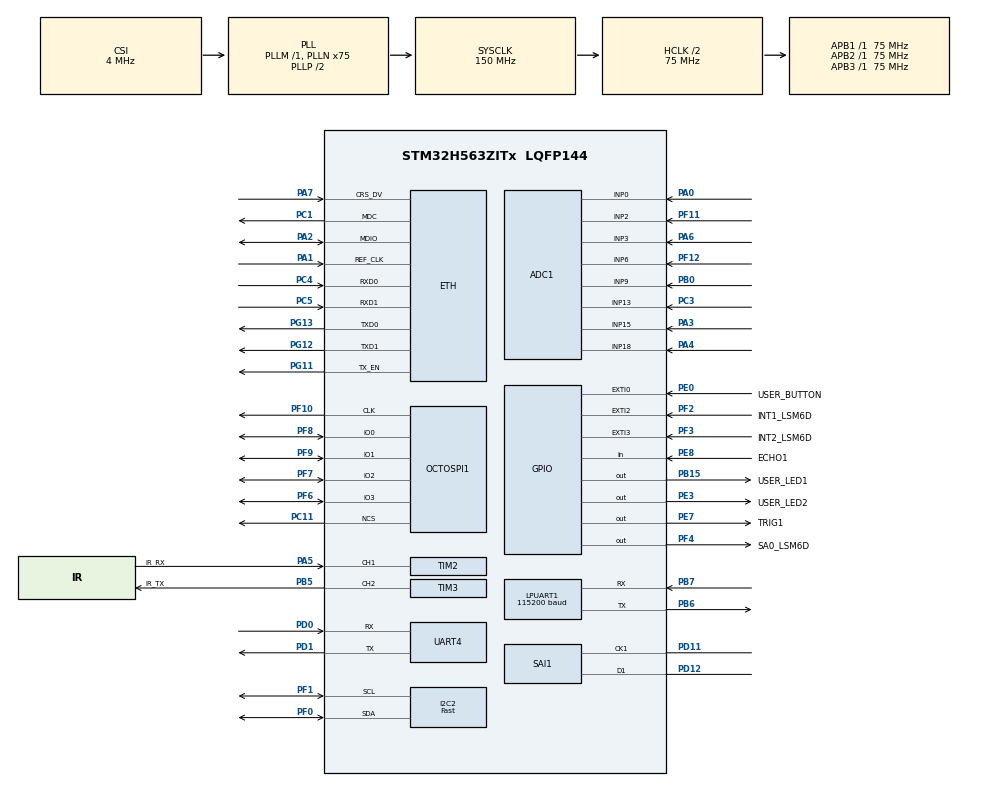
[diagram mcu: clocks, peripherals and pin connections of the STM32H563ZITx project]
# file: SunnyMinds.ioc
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ADC1.Channel-1\#ChannelRegularConversion=ADC_CHANNEL_2
ADC1.Channel-2\#ChannelRegularConversion=ADC_CHANNEL_6
ADC1.Channel-3\#ChannelRegularConversion=ADC_CHANNEL_18
ADC1.Channel-4\#ChannelRegularConversion=ADC_CHANNEL_3
ADC1.Channel-5\#ChannelRegularConversion=ADC_CHANNEL_0
ADC1.Channel-6\#ChannelRegularConversion=ADC_CHANNEL_9
ADC1.Channel-7\#ChannelRegularConversion=ADC_CHANNEL_15
ADC1.Channel-8\#ChannelRegularConversion=ADC_CHANNEL_13
ADC1.ClockPrescaler=ADC_CLOCK_ASYNC_DIV32
ADC1.ContinuousConvMode=ENABLE
ADC1.DMAContinuousRequests=ENABLE
ADC1.MonitoredBy-1\#ChannelRegularConversion=__NULL
ADC1.MonitoredBy-2\#ChannelRegularConversion=__NULL
ADC1.MonitoredBy-3\#ChannelRegularConversion=__NULL
ADC1.MonitoredBy-4\#ChannelRegularConversion=__NULL
ADC1.MonitoredBy-5\#ChannelRegularConversion=__NULL
ADC1.MonitoredBy-6\#ChannelRegularConversion=__NULL
ADC1.MonitoredBy-7\#ChannelRegularConversion=__NULL
ADC1.MonitoredBy-8\#ChannelRegularConversion=__NULL
ADC1.NbrOfConversion=8
ADC1.NbrOfConversionFlag=1
ADC1.OffsetNumber-1\#ChannelRegularConversion=ADC_OFFSET_NONE
ADC1.OffsetNumber-2\#ChannelRegularConversion=ADC_OFFSET_NONE
ADC1.OffsetNumber-3\#ChannelRegularConversion=ADC_OFFSET_NONE
ADC1.OffsetNumber-4\#ChannelRegularConversion=ADC_OFFSET_NONE
ADC1.OffsetNumber-5\#ChannelRegularConversion=ADC_OFFSET_NONE
ADC1.OffsetNumber-6\#ChannelRegularConversion=ADC_OFFSET_NONE
ADC1.OffsetNumber-7\#ChannelRegularConversion=ADC_OFFSET_NONE
ADC1.OffsetNumber-8\#ChannelRegularConversion=ADC_OFFSET_NONE
ADC1.Rank-1\#ChannelRegularConversion=1
ADC1.Rank-2\#ChannelRegularConversion=2
ADC1.Rank-3\#ChannelRegularConversion=3
ADC1.Rank-4\#ChannelRegularConversion=4
ADC1.Rank-5\#ChannelRegularConversion=5
ADC1.Rank-6\#ChannelRegularConversion=6
ADC1.Rank-7\#ChannelRegularConversion=7
ADC1.Rank-8\#ChannelRegularConversion=8
ADC1.SamplingTime-1\#ChannelRegularConversion=ADC_SAMPLETIME_247CYCLES_5
ADC1.SamplingTime-2\#ChannelRegularConversion=ADC_SAMPLETIME_247CYCLES_5
ADC1.SamplingTime-3\#ChannelRegularConversion=ADC_SAMPLETIME_247CYCLES_5
ADC1.SamplingTime-4\#ChannelRegularConversion=ADC_SAMPLETIME_640CYCLES_5
ADC1.SamplingTime-5\#ChannelRegularConversion=ADC_SAMPLETIME_247CYCLES_5
ADC1.SamplingTime-6\#ChannelRegularConversion=ADC_SAMPLETIME_247CYCLES_5
ADC1.SamplingTime-7\#ChannelRegularConversion=ADC_SAMPLETIME_247CYCLES_5
ADC1.SamplingTime-8\#ChannelRegularConversion=ADC_SAMPLETIME_247CYCLES_5
ADC1.master=1
BOOTPATH.BootPathName=LEGACY
BOOTPATH.UserSelectedBootPath=LEGACY
CORTEX_M33_NS.userName=CORTEX_M33
ETH.MediaInterface=HAL_ETH_RMII_MODE
GPDMA1.CIRCULARMODE_GPDMACH2=ENABLE
GPDMA1.CIRCULARMODE_GPDMACH7=ENABLE
GPDMA1.DESTDATAWIDTH_GPDMACH1=DMA_DEST_DATAWIDTH_WORD
GPDMA1.DESTDATAWIDTH_GPDMACH2=DMA_DEST_DATAWIDTH_HALFWORD
GPDMA1.DESTDATAWIDTH_GPDMACH7=DMA_DEST_DATAWIDTH_HALFWORD
GPDMA1.DESTINC_GPDMACH1=DMA_DINC_INCREMENTED
GPDMA1.DESTINC_GPDMACH2=DMA_DINC_INCREMENTED
GPDMA1.DESTINC_GPDMACH7=DMA_DINC_INCREMENTED
GPDMA1.IPHANDLE_GPDMACH1-SIMPLEREQUEST_GPDMACH1=__NULL
GPDMA1.IPHANDLE_GPDMACH2-SIMPLEREQUEST_GPDMACH2=__NULL
GPDMA1.IPHANDLE_GPDMACH7-SIMPLEREQUEST_GPDMACH7=__NULL
GPDMA1.LINKALLOCATEDPORT_CIRCULAR_GPDMACH2=DMA_LINK_ALLOCATED_PORT1
GPDMA1.REQUEST_GPDMACH1=GPDMA1_REQUEST_TIM2_CH1
GPDMA1.REQUEST_GPDMACH2=GPDMA1_REQUEST_SAI1_A
GPDMA1.REQUEST_GPDMACH7=GPDMA1_REQUEST_ADC1
GPDMA1.SRCDATAWIDTH_GPDMACH1=DMA_SRC_DATAWIDTH_HALFWORD
GPDMA1.SRCDATAWIDTH_GPDMACH2=DMA_SRC_DATAWIDTH_HALFWORD
GPDMA1.SRCDATAWIDTH_GPDMACH7=DMA_SRC_DATAWIDTH_HALFWORD
GPDMA1.TRANSFERALLOCATEDPORTDEST_GPDMACH1=DMA_DEST_ALLOCATED_PORT1
GPDMA1.TRANSFERALLOCATEDPORTDEST_GPDMACH2=DMA_DEST_ALLOCATED_PORT1
GPDMA1.TRANSFERALLOCATEDPORTSRC_GPDMACH1=DMA_SRC_ALLOCATED_PORT1
GPDMA1.TRANSFERALLOCATEDPORTSRC_GPDMACH2=DMA_SRC_ALLOCATED_PORT1
I2C2.I2C_Speed_Mode=I2C_Fast
I2C2.Timing=0x00702787
LPUART1.BaudRate=115200
Mcu.Family=STM32H5
Mcu.Name=STM32H563ZITx
Mcu.Package=LQFP144
NETXDUO.ETH_ON=1
NETXDUO.LAN_8742=1
NETXDUO.NX_APP_IP_INSTANCE_THREAD_SIZE=2*1024
NETXDUO.NX_APP_MEM_POOL_SIZE=30*1024
NETXDUO.NX_APP_PACKET_POOL_SIZE=10
NETXDUO.NX_APP_THREAD_STACK_SIZE=2*1024
NETXDUO.NX_ENABLE_INTERFACE_CAPABILITY=true
NETXDUO.NetXDuo_Generate_Init_Code=true
NVIC.ETH_IRQn=true\:0\:0\:false\:false\:true\:false\:true\:true\:true
NVIC.EXTI0_IRQn=true\:0\:0\:false\:false\:true\:false\:true\:true\:true
NVIC.GPDMA1_Channel1_IRQn=true\:0\:0\:false\:false\:true\:true\:false\:true\:true
NVIC.GPDMA1_Channel2_IRQn=true\:0\:0\:false\:false\:true\:true\:false\:true\:true
NVIC.GPDMA1_Channel7_IRQn=true\:0\:0\:false\:false\:true\:true\:false\:true\:true
NVIC.LPUART1_IRQn=true\:0\:0\:false\:false\:true\:false\:true\:true\:true
NVIC.PriorityGroup=NVIC_PRIORITYGROUP_4
NVIC.TIM17_IRQn=true\:0\:0\:false\:false\:true\:false\:true\:true\:true
NVIC.TIM3_IRQn=true\:0\:0\:false\:false\:true\:false\:true\:true\:true
NVIC.TIM6_IRQn=true\:15\:0\:false\:false\:true\:false\:false\:true\:true
NVIC.TimeBase=TIM6_IRQn
NVIC.TimeBaseIP=TIM6
NetXDuo.BSP.number=1
NetXDuo0.BSP.STBoard=false
NetXDuo0.BSP.api=BSP_COMPONENT_DRIVER
NetXDuo0.BSP.component=lan8742
NetXDuo0.BSP.instance=lan8742
NetXDuo0.BSP.name=LAN_Component
NetXDuo0.BSP.semaphore=SEMA_lan8742
NetXDuo0.BSP.solution=lan8742
OCTOSPI1.ChipSelectHighTimeCycle=6
OCTOSPI1.ClockPrescaler=3-1
OCTOSPI1.DeviceType=SPI_DEVICE_FLASH
OCTOSPI1.FifoThresholdByte=1
OCTOSPI1.MemorySize=HAL_XSPI_SIZE_1MB
OCTOSPI1.SampleShifting=HAL_XSPI_SAMPLE_SHIFT_HALFCYCLE
PA0.Signal=ADCx_INP0
PA1.Mode=RMII
PA1.Signal=ETH_REF_CLK
PA2.Mode=RMII
PA2.Signal=ETH_MDIO
PA3.Signal=ADCx_INP15
PA4.Signal=ADCx_INP18
PA5.GPIO_Label=IR_RX
PA5.Signal=S_TIM2_CH1
PA6.Signal=ADCx_INP3
PA7.Mode=RMII
PA7.Signal=ETH_CRS_DV
PB0.Signal=ADCx_INP9
PB15.GPIO_Label=USER_LED1
PB15.Signal=GPIO_Output
PB5.GPIO_Label=IR_TX
PB5.Signal=S_TIM3_CH2
PB6.Mode=Asynchronous
PB6.Signal=LPUART1_TX
PB7.Mode=Asynchronous
PB7.Signal=LPUART1_RX
PC1.Mode=RMII
PC1.Signal=ETH_MDC
PC11.Mode=quad_mode
PC11.Signal=OCTOSPI1_NCS
PC3.Signal=ADCx_INP13
PC4.Mode=RMII
PC4.Signal=ETH_RXD0
PC5.Mode=RMII
PC5.Signal=ETH_RXD1
PD0.Mode=Asynchronous
PD0.Signal=UART4_RX
PD1.Mode=Asynchronous
PD1.Signal=UART4_TX
PD11.Mode=PDM_Master_Mode_CK1
PD11.Signal=SAI1_CK1
PD12.Mode=PDM_Master_Mode_CK1
PD12.Signal=SAI1_D1
PE0.GPIO_Label=USER_BUTTON
PE0.Signal=GPXTI0
PE3.GPIO_Label=USER_LED2
PE3.PinAttribute=Free
PE3.Signal=GPIO_Output
PE7.GPIO_Label=TRIG1
PE7.Signal=GPIO_Output
PE8.GPIO_Label=ECHO1
PE8.Signal=GPIO_Input
PF0.Mode=I2C
PF0.Signal=I2C2_SDA
PF1.Mode=I2C
PF1.Signal=I2C2_SCL
PF10.Mode=quad_mode
PF10.Signal=OCTOSPI1_CLK
PF11.Mode=IN2-Single-Ended
PF11.Signal=ADC1_INP2
PF12.Mode=IN6-Single-Ended
PF12.Signal=ADC1_INP6
PF2.GPIO_Label=INT1_LSM6D
PF2.Signal=GPXTI2
PF3.GPIO_Label=INT2_LSM6D
PF3.Signal=GPXTI3
PF4.GPIO_Label=SA0_LSM6D
PF4.Signal=GPIO_Output
PF6.Mode=OCTOSPI1_IO[3\:0]
PF6.Signal=OCTOSPI1_IO3
PF7.Mode=OCTOSPI1_IO[3\:0]
PF7.Signal=OCTOSPI1_IO2
PF8.Mode=OCTOSPI1_IO[3\:0]
PF8.Signal=OCTOSPI1_IO0
PF9.Mode=OCTOSPI1_IO[3\:0]
PF9.Signal=OCTOSPI1_IO1
PG11.Mode=RMII
PG11.Signal=ETH_TX_EN
PG12.Mode=RMII
PG12.Signal=ETH_TXD1
PG13.Mode=RMII
PG13.Signal=ETH_TXD0
ProjectManager.HeapSize=0x200
ProjectManager.StackSize=0x400
ProjectManager.TargetToolchain=STM32CubeIDE
RCC.ADCFreq_Value=75000000
RCC.AHBCLKDivider=RCC_SYSCLK_DIV2
RCC.AHBFreq_Value=75000000
RCC.APB1Freq_Value=75000000
RCC.APB1TimFreq_Value=75000000
RCC.APB2Freq_Value=75000000
RCC.APB2TimFreq_Value=75000000
RCC.APB3Freq_Value=75000000
RCC.CSI_VALUE=4000000
RCC.CortexFreq_Value=75000000
RCC.EPOD_VALUE=4000000
RCC.HCLKFreq_Value=75000000
RCC.HSE_VALUE=25000000
RCC.HSI48_VALUE=48000000
RCC.HSI_VALUE=64000000
RCC.LSE_VALUE=32768
RCC.LSIRC_VALUE=32000
RCC.PLL1Q=3
RCC.PLL2FRACN=0
RCC.PLL2N=64
RCC.PLL2P=125
RCC.PLL3FRACN=0
RCC.PLLFRACN=0
RCC.PLLN=75
RCC.SYSCLKFreq_VALUE=150000000
RCC.SYSCLKSource=RCC_SYSCLKSOURCE_PLLCLK
RCC.USBFreq_Value=48000000
RCC.VCOOutputFreq_Value=300000000
SAI1.Activation=ENABLE
SAI1.AudioFrequency-PDM_Master_Mode_CK1=SAI_AUDIO_FREQUENCY_96K
SAI1.DataSize-PDM_Master_Mode_CK1=SAI_DATASIZE_8
SAI1.ErrorAudioFreq-PDM_Master_Mode_CK1=-91.66 %
SAI1.FSPolarity-PDM_Master_Mode_CK1=SAI_FS_ACTIVE_LOW
SAI1.FrameLength-PDM_Master_Mode_CK1=16
SAI1.Instance-PDM_Master_Mode_CK1=SAI$Index_Block_A
SAI1.MckOutput-PDM_Master_Mode_CK1=SAI_MCK_OUTPUT_DISABLE
SAI1.NoDivider-PDM_Master_Mode_CK1=SAI_MASTERDIVIDER_ENABLE
SAI1.RealAudioFreq-PDM_Master_Mode_CK1=8.0 KHz
SAI1.SlotActive-PDM_Master_Mode_CK1=0x0000FFFF
SAI1.VirtualMode-PDM_Master_Mode_CK1=VM_MASTER
SAI1.VirtualProtocol-PDM_Master_Mode_CK1=VM_PDM_PROTOCOL
SAI1.VirtualSlotActive-PDM_Master_Mode_CK1=SAI_SLOTACTIVE_ALL
SH.ADCx_INP0.0=ADC1_INP0,IN0-Single-Ended
SH.ADCx_INP13.0=ADC1_INP13,IN13-Single-Ended
SH.ADCx_INP15.0=ADC1_INP15,IN15-Single-Ended
SH.ADCx_INP18.0=ADC1_INP18,IN18-Single-Ended
SH.ADCx_INP3.0=ADC1_INP3,IN3-Single-Ended
SH.ADCx_INP9.0=ADC1_INP9,IN9-Single-Ended
SH.S_TIM2_CH1.0=TIM2_CH1,Input_Capture1_from_TI1
SH.S_TIM3_CH2.0=TIM3_CH2,PWM Generation2 CH2
STMicroelectronics.X-CUBE-MEMS1.10.0.0.BoardOoPartJjAccGyrJjLSM6DSL=I2C
STMicroelectronics.X-CUBE-MEMS1.10.0.0.BoardOoPartJjMagJjLIS2MDL=I2C
STMicroelectronics.X-CUBE-MEMS1.10.0.0.SensorsJjSTM32IiMotionFXIiLibraryJjCore=true
TIM16.Prescaler=75-1
TIM17.Prescaler=75-1
TIM2.Channel-Input_Capture1_from_TI1=TIM_CHANNEL_1
TIM2.ICFilter_CH1=15
TIM2.ICPolarity_CH1=TIM_INPUTCHANNELPOLARITY_FALLING
TIM2.PeriodNoDither=65535
TIM2.Prescaler=75-1
TIM3.Channel-PWM\ Generation2\ CH2=TIM_CHANNEL_2
TIM3.PeriodNoDither=18-1
TIM3.Prescaler=250-1
VP_BOOTPATH_VS_BOOTPATH.Mode=BP_Activate
VP_CORTEX_M33_NS_VS_Hclk.Mode=Hclk_Mode
VP_CRC_VS_CRC.Mode=CRC_Activate
VP_GPDMA1_VS_GPDMACH1.Mode=SIMPLEREQUEST_GPDMACH1
VP_GPDMA1_VS_GPDMACH2.Mode=SIMPLEREQUEST_GPDMACH2
VP_GPDMA1_VS_GPDMACH7.Mode=SIMPLEREQUEST_GPDMACH7
VP_ICACHE_VS_ICACHE.Mode=DefaultMode
VP_MEMORYMAP_VS_MEMORYMAP.Mode=CurAppReg
VP_NETXDUO_VS_AddonsOoDHCP.Mode=Addons_DHCP_Client
VP_NETXDUO_VS_EthernetOoPhyOoInterface.Mode=LAN8742_Phy_Interface
VP_NETXDUO_VS_NXOoCore.Mode=NX_Core
VP_NETXDUO_VS_NetworkOoInterface.Mode=Ethernet_Interface
VP_PWR_VS_DBSignals.Mode=DisableDeadBatterySignals
VP_PWR_VS_LPOM.Mode=PowerOptimisation
VP_PWR_VS_SECSignals.Mode=Security/Privilege
VP_STMicroelectronics.X-CUBE-MEMS1_VS_BoardOoPartJjAccGyr_5.5.0_10.0.0.Mode=BoardOoPartJjAccGyr
VP_STMicroelectronics.X-CUBE-MEMS1_VS_BoardOoPartJjMag_5.4.0_10.0.0.Mode=BoardOoPartJjMag
VP_STMicroelectronics.X-CUBE-MEMS1_VS_SensorsJjSTM32IiMotionFXIiLibrary_2.8.0_10.0.0.Mode=SensorsJjSTM32IiMotionFXIiLibrary
VP_SYS_VS_tim6.Mode=TIM6
VP_THREADX_VS_RTOSJjThreadXJjCoreJjDefault.Mode=Core_Default
VP_TIM16_VS_ClockSourceINT.Mode=Enable_Timer
VP_TIM17_VS_ClockSourceINT.Mode=Enable_Timer
VP_TIM2_VS_ClockSourceINT.Mode=Internal
VP_TIM3_VS_ClockSourceINT.Mode=Internal
board=custom

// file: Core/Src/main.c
/* USER CODE BEGIN Header */
/**
  ******************************************************************************
  * @file           : main.c
  * @brief          : Main program body
  ******************************************************************************
  * @attention
  *
  * Copyright (c) 2024 STMicroelectronics.
  * All rights reserved.
  *
  * This software is licensed under terms that can be found in the LICENSE file
  * in the root directory of this software component.
  * If no LICENSE file comes with this software, it is provided AS-IS.
  *
  ******************************************************************************
  */
/* USER CODE END Header */
#include "app_threadx.h"
#include "main.h"
#include "string.h"

ETH_TxPacketConfigTypeDef TxConfig;
ETH_DMADescTypeDef  DMARxDscrTab[ETH_RX_DESC_CNT]; /* Ethernet Rx DMA Descriptors */
ETH_DMADescTypeDef  DMATxDscrTab[ETH_TX_DESC_CNT]; /* Ethernet Tx DMA Descriptors */

ADC_HandleTypeDef hadc1;
DMA_NodeTypeDef Node_GPDMA1_Channel7;
DMA_QListTypeDef List_GPDMA1_Channel7;
DMA_HandleTypeDef handle_GPDMA1_Channel7;

CRC_HandleTypeDef hcrc;

ETH_HandleTypeDef heth;

I2C_HandleTypeDef hi2c2;

UART_HandleTypeDef hlpuart1;
UART_HandleTypeDef huart4;

XSPI_HandleTypeDef hospi1;

SAI_HandleTypeDef hsai_BlockA1;
DMA_NodeTypeDef Node_GPDMA1_Channel2;
DMA_QListTypeDef List_GPDMA1_Channel2;
DMA_HandleTypeDef handle_GPDMA1_Channel2;

TIM_HandleTypeDef htim2;
TIM_HandleTypeDef htim3;
TIM_HandleTypeDef htim16;
TIM_HandleTypeDef htim17;
DMA_HandleTypeDef handle_GPDMA1_Channel1;

void SystemClock_Config(void);
static void MX_GPIO_Init(void);
static void MX_GPDMA1_Init(void);
static void MX_OCTOSPI1_Init(void);
static void MX_ETH_Init(void);
static void MX_ICACHE_Init(void);
static void MX_TIM17_Init(void);
static void MX_TIM2_Init(void);
static void MX_TIM3_Init(void);
static void MX_CRC_Init(void);
static void MX_LPUART1_UART_Init(void);
static void MX_UART4_Init(void);
static void MX_I2C2_Init(void);
static void MX_SAI1_Init(void);
static void MX_ADC1_Init(void);
static void MX_TIM16_Init(void);

int main(void)
{

  /* MCU Configuration--------------------------------------------------------*/

  /* Reset of all peripherals, Initializes the Flash interface and the Systick. */
  HAL_Init();

  /* Configure the system clock */
  SystemClock_Config();

  /* Initialize all configured peripherals */
  MX_GPIO_Init();
  MX_GPDMA1_Init();
  MX_OCTOSPI1_Init();
  MX_ETH_Init();
  MX_ICACHE_Init();
  MX_TIM17_Init();
  MX_TIM2_Init();
  MX_TIM3_Init();
  MX_CRC_Init();
  MX_LPUART1_UART_Init();
  MX_UART4_Init();
  MX_I2C2_Init();
  MX_SAI1_Init();
  MX_ADC1_Init();
  MX_TIM16_Init();
  /* USER CODE BEGIN 2 */

  // clear terminal screen for coolterm
  printf("\e[1;1H\e[2J");fflush(stdout);

  printf("\r\nHello SunnyMinds \r\n");
  /* USER CODE END 2 */

  MX_ThreadX_Init();

  /* We should never get here as control is now taken by the scheduler */

  /* Infinite loop */
  while (1)
  {

  }
}

void SystemClock_Config(void)
{
  RCC_OscInitTypeDef RCC_OscInitStruct = {0};
  RCC_ClkInitTypeDef RCC_ClkInitStruct = {0};

  /** Configure the main internal regulator output voltage
  */
  __HAL_PWR_VOLTAGESCALING_CONFIG(PWR_REGULATOR_VOLTAGE_SCALE2);

  while(!__HAL_PWR_GET_FLAG(PWR_FLAG_VOSRDY)) {}

  /** Initializes the RCC Oscillators according to the specified parameters
  * in the RCC_OscInitTypeDef structure.
  */
  RCC_OscInitStruct.OscillatorType = RCC_OSCILLATORTYPE_CSI;
  RCC_OscInitStruct.CSIState = RCC_CSI_ON;
  RCC_OscInitStruct.CSICalibrationValue = RCC_CSICALIBRATION_DEFAULT;
  RCC_OscInitStruct.PLL.PLLState = RCC_PLL_ON;
  RCC_OscInitStruct.PLL.PLLSource = RCC_PLL1_SOURCE_CSI;
  RCC_OscInitStruct.PLL.PLLM = 1;
  RCC_OscInitStruct.PLL.PLLN = 75;
  RCC_OscInitStruct.PLL.PLLP = 2;
  RCC_OscInitStruct.PLL.PLLQ = 3;
  RCC_OscInitStruct.PLL.PLLR = 2;
  RCC_OscInitStruct.PLL.PLLRGE = RCC_PLL1_VCIRANGE_2;
  RCC_OscInitStruct.PLL.PLLVCOSEL = RCC_PLL1_VCORANGE_WIDE;
  RCC_OscInitStruct.PLL.PLLFRACN = 0;
  if (HAL_RCC_OscConfig(&RCC_OscInitStruct) != HAL_OK)
  {
    Error_Handler();
  }

  /** Initializes the CPU, AHB and APB buses clocks
  */
  RCC_ClkInitStruct.ClockType = RCC_CLOCKTYPE_HCLK|RCC_CLOCKTYPE_SYSCLK
                              |RCC_CLOCKTYPE_PCLK1|RCC_CLOCKTYPE_PCLK2
                              |RCC_CLOCKTYPE_PCLK3;
  RCC_ClkInitStruct.SYSCLKSource = RCC_SYSCLKSOURCE_PLLCLK;
  RCC_ClkInitStruct.AHBCLKDivider = RCC_SYSCLK_DIV2;
  RCC_ClkInitStruct.APB1CLKDivider = RCC_HCLK_DIV1;
  RCC_ClkInitStruct.APB2CLKDivider = RCC_HCLK_DIV1;
  RCC_ClkInitStruct.APB3CLKDivider = RCC_HCLK_DIV1;

  if (HAL_RCC_ClockConfig(&RCC_ClkInitStruct, FLASH_LATENCY_4) != HAL_OK)
  {
    Error_Handler();
  }
}

static void MX_ADC1_Init(void)
{

  ADC_ChannelConfTypeDef sConfig = {0};

  /** Common config
  */
  hadc1.Instance = ADC1;
  hadc1.Init.ClockPrescaler = ADC_CLOCK_ASYNC_DIV32;
  hadc1.Init.Resolution = ADC_RESOLUTION_12B;
  hadc1.Init.DataAlign = ADC_DATAALIGN_RIGHT;
  hadc1.Init.ScanConvMode = ADC_SCAN_ENABLE;
  hadc1.Init.EOCSelection = ADC_EOC_SINGLE_CONV;
  hadc1.Init.LowPowerAutoWait = DISABLE;
  hadc1.Init.ContinuousConvMode = ENABLE;
  hadc1.Init.NbrOfConversion = 8;
  hadc1.Init.DiscontinuousConvMode = DISABLE;
  hadc1.Init.ExternalTrigConv = ADC_SOFTWARE_START;
  hadc1.Init.ExternalTrigConvEdge = ADC_EXTERNALTRIGCONVEDGE_NONE;
  hadc1.Init.DMAContinuousRequests = ENABLE;
  hadc1.Init.SamplingMode = ADC_SAMPLING_MODE_NORMAL;
  hadc1.Init.Overrun = ADC_OVR_DATA_PRESERVED;
  hadc1.Init.OversamplingMode = DISABLE;
  if (HAL_ADC_Init(&hadc1) != HAL_OK)
  {
    Error_Handler();
  }

  /** Configure Regular Channel
  */
  sConfig.Channel = ADC_CHANNEL_2;
  sConfig.Rank = ADC_REGULAR_RANK_1;
  sConfig.SamplingTime = ADC_SAMPLETIME_247CYCLES_5;
  sConfig.SingleDiff = ADC_SINGLE_ENDED;
  sConfig.OffsetNumber = ADC_OFFSET_NONE;
  sConfig.Offset = 0;
  if (HAL_ADC_ConfigChannel(&hadc1, &sConfig) != HAL_OK)
  {
    Error_Handler();
  }

  /** Configure Regular Channel
  */
  sConfig.Channel = ADC_CHANNEL_6;
  sConfig.Rank = ADC_REGULAR_RANK_2;
  if (HAL_ADC_ConfigChannel(&hadc1, &sConfig) != HAL_OK)
  {
    Error_Handler();
  }

  /** Configure Regular Channel
  */
  sConfig.Channel = ADC_CHANNEL_18;
  sConfig.Rank = ADC_REGULAR_RANK_3;
  if (HAL_ADC_ConfigChannel(&hadc1, &sConfig) != HAL_OK)
  {
    Error_Handler();
  }

  /** Configure Regular Channel
  */
  sConfig.Channel = ADC_CHANNEL_3;
  sConfig.Rank = ADC_REGULAR_RANK_4;
  sConfig.SamplingTime = ADC_SAMPLETIME_640CYCLES_5;
  if (HAL_ADC_ConfigChannel(&hadc1, &sConfig) != HAL_OK)
  {
    Error_Handler();
  }

  /** Configure Regular Channel
  */
  sConfig.Channel = ADC_CHANNEL_0;
  sConfig.Rank = ADC_REGULAR_RANK_5;
  sConfig.SamplingTime = ADC_SAMPLETIME_247CYCLES_5;
  if (HAL_ADC_ConfigChannel(&hadc1, &sConfig) != HAL_OK)
  {
    Error_Handler();
  }

  /** Configure Regular Channel
  */
  sConfig.Channel = ADC_CHANNEL_9;
  sConfig.Rank = ADC_REGULAR_RANK_6;
  if (HAL_ADC_ConfigChannel(&hadc1, &sConfig) != HAL_OK)
  {
    Error_Handler();
  }

  /** Configure Regular Channel
  */
  sConfig.Channel = ADC_CHANNEL_15;
  sConfig.Rank = ADC_REGULAR_RANK_7;
  if (HAL_ADC_ConfigChannel(&hadc1, &sConfig) != HAL_OK)
  {
    Error_Handler();
  }

  /** Configure Regular Channel
  */
  sConfig.Channel = ADC_CHANNEL_13;
  sConfig.Rank = ADC_REGULAR_RANK_8;
  if (HAL_ADC_ConfigChannel(&hadc1, &sConfig) != HAL_OK)
  {
    Error_Handler();
  }

}

static void MX_CRC_Init(void)
{

  hcrc.Instance = CRC;
  hcrc.Init.DefaultPolynomialUse = DEFAULT_POLYNOMIAL_ENABLE;
  hcrc.Init.DefaultInitValueUse = DEFAULT_INIT_VALUE_ENABLE;
  hcrc.Init.InputDataInversionMode = CRC_INPUTDATA_INVERSION_NONE;
  hcrc.Init.OutputDataInversionMode = CRC_OUTPUTDATA_INVERSION_DISABLE;
  hcrc.InputDataFormat = CRC_INPUTDATA_FORMAT_BYTES;
  if (HAL_CRC_Init(&hcrc) != HAL_OK)
  {
    Error_Handler();
  }

}

static void MX_ETH_Init(void)
{

   static uint8_t MACAddr[6];

  heth.Instance = ETH;
  MACAddr[0] = 0x00;
  MACAddr[1] = 0x80;
  MACAddr[2] = 0xE1;
  MACAddr[3] = 0x00;
  MACAddr[4] = 0x00;
  MACAddr[5] = 0x00;
  heth.Init.MACAddr = &MACAddr[0];
  heth.Init.MediaInterface = HAL_ETH_RMII_MODE;
  heth.Init.TxDesc = DMATxDscrTab;
  heth.Init.RxDesc = DMARxDscrTab;
  heth.Init.RxBuffLen = 1524;

  if (HAL_ETH_Init(&heth) != HAL_OK)
  {
    Error_Handler();
  }

  memset(&TxConfig, 0 , sizeof(ETH_TxPacketConfigTypeDef));
  TxConfig.Attributes = ETH_TX_PACKETS_FEATURES_CSUM | ETH_TX_PACKETS_FEATURES_CRCPAD;
  TxConfig.ChecksumCtrl = ETH_CHECKSUM_IPHDR_PAYLOAD_INSERT_PHDR_CALC;
  TxConfig.CRCPadCtrl = ETH_CRC_PAD_INSERT;

}

static void MX_GPDMA1_Init(void)
{

  /* Peripheral clock enable */
  __HAL_RCC_GPDMA1_CLK_ENABLE();

  /* GPDMA1 interrupt Init */
    HAL_NVIC_SetPriority(GPDMA1_Channel1_IRQn, 0, 0);
    HAL_NVIC_EnableIRQ(GPDMA1_Channel1_IRQn);
    HAL_NVIC_SetPriority(GPDMA1_Channel2_IRQn, 0, 0);
    HAL_NVIC_EnableIRQ(GPDMA1_Channel2_IRQn);
    HAL_NVIC_SetPriority(GPDMA1_Channel7_IRQn, 0, 0);
    HAL_NVIC_EnableIRQ(GPDMA1_Channel7_IRQn);

}

static void MX_I2C2_Init(void)
{

  hi2c2.Instance = I2C2;
  hi2c2.Init.Timing = 0x00702787;
  hi2c2.Init.OwnAddress1 = 0;
  hi2c2.Init.AddressingMode = I2C_ADDRESSINGMODE_7BIT;
  hi2c2.Init.DualAddressMode = I2C_DUALADDRESS_DISABLE;
  hi2c2.Init.OwnAddress2 = 0;
  hi2c2.Init.OwnAddress2Masks = I2C_OA2_NOMASK;
  hi2c2.Init.GeneralCallMode = I2C_GENERALCALL_DISABLE;
  hi2c2.Init.NoStretchMode = I2C_NOSTRETCH_DISABLE;
  if (HAL_I2C_Init(&hi2c2) != HAL_OK)
  {
    Error_Handler();
  }

  /** Configure Analogue filter
  */
  if (HAL_I2CEx_ConfigAnalogFilter(&hi2c2, I2C_ANALOGFILTER_ENABLE) != HAL_OK)
  {
    Error_Handler();
  }

  /** Configure Digital filter
  */
  if (HAL_I2CEx_ConfigDigitalFilter(&hi2c2, 0) != HAL_OK)
  {
    Error_Handler();
  }

}

static void MX_ICACHE_Init(void)
{

  /** Enable instruction cache (default 2-ways set associative cache)
  */
  if (HAL_ICACHE_Enable() != HAL_OK)
  {
    Error_Handler();
  }

}

static void MX_LPUART1_UART_Init(void)
{

  hlpuart1.Instance = LPUART1;
  hlpuart1.Init.BaudRate = 115200;
  hlpuart1.Init.WordLength = UART_WORDLENGTH_8B;
  hlpuart1.Init.StopBits = UART_STOPBITS_1;
  hlpuart1.Init.Parity = UART_PARITY_NONE;
  hlpuart1.Init.Mode = UART_MODE_TX_RX;
  hlpuart1.Init.HwFlowCtl = UART_HWCONTROL_NONE;
  hlpuart1.Init.OneBitSampling = UART_ONE_BIT_SAMPLE_DISABLE;
  hlpuart1.AdvancedInit.AdvFeatureInit = UART_ADVFEATURE_NO_INIT;
  hlpuart1.FifoMode = UART_FIFOMODE_DISABLE;
  if (HAL_UART_Init(&hlpuart1) != HAL_OK)
  {
    Error_Handler();
  }
  if (HAL_UARTEx_SetTxFifoThreshold(&hlpuart1, UART_TXFIFO_THRESHOLD_1_8) != HAL_OK)
  {
    Error_Handler();
  }
  if (HAL_UARTEx_SetRxFifoThreshold(&hlpuart1, UART_RXFIFO_THRESHOLD_1_8) != HAL_OK)
  {
    Error_Handler();
  }
  if (HAL_UARTEx_DisableFifoMode(&hlpuart1) != HAL_OK)
  {
    Error_Handler();
  }

}

static void MX_UART4_Init(void)
{

  huart4.Instance = UART4;
  huart4.Init.BaudRate = 115200;
  huart4.Init.WordLength = UART_WORDLENGTH_8B;
  huart4.Init.StopBits = UART_STOPBITS_1;
  huart4.Init.Parity = UART_PARITY_NONE;
  huart4.Init.Mode = UART_MODE_TX_RX;
  huart4.Init.HwFlowCtl = UART_HWCONTROL_NONE;
  huart4.Init.OverSampling = UART_OVERSAMPLING_16;
  huart4.Init.OneBitSampling = UART_ONE_BIT_SAMPLE_DISABLE;
  huart4.Init.ClockPrescaler = UART_PRESCALER_DIV1;
  huart4.AdvancedInit.AdvFeatureInit = UART_ADVFEATURE_NO_INIT;
  if (HAL_UART_Init(&huart4) != HAL_OK)
  {
    Error_Handler();
  }
  if (HAL_UARTEx_SetTxFifoThreshold(&huart4, UART_TXFIFO_THRESHOLD_1_8) != HAL_OK)
  {
    Error_Handler();
  }
  if (HAL_UARTEx_SetRxFifoThreshold(&huart4, UART_RXFIFO_THRESHOLD_1_8) != HAL_OK)
  {
    Error_Handler();
  }
  if (HAL_UARTEx_DisableFifoMode(&huart4) != HAL_OK)
  {
    Error_Handler();
  }

}

static void MX_OCTOSPI1_Init(void)
{

  /* OCTOSPI1 parameter configuration*/
  hospi1.Instance = OCTOSPI1;
  hospi1.Init.FifoThresholdByte = 1;
  hospi1.Init.MemoryMode = HAL_XSPI_SINGLE_MEM;
  hospi1.Init.MemoryType = HAL_XSPI_MEMTYPE_MICRON;
  hospi1.Init.MemorySize = HAL_XSPI_SIZE_1MB;
  hospi1.Init.ChipSelectHighTimeCycle = 6;
  hospi1.Init.FreeRunningClock = HAL_XSPI_FREERUNCLK_DISABLE;
  hospi1.Init.ClockMode = HAL_XSPI_CLOCK_MODE_0;
  hospi1.Init.WrapSize = HAL_XSPI_WRAP_NOT_SUPPORTED;
  hospi1.Init.ClockPrescaler = 3-1;
  hospi1.Init.SampleShifting = HAL_XSPI_SAMPLE_SHIFT_HALFCYCLE;
  hospi1.Init.DelayHoldQuarterCycle = HAL_XSPI_DHQC_DISABLE;
  hospi1.Init.ChipSelectBoundary = HAL_XSPI_BONDARYOF_NONE;
  hospi1.Init.DelayBlockBypass = HAL_XSPI_DELAY_BLOCK_BYPASS;
  hospi1.Init.Refresh = 0;
  if (HAL_XSPI_Init(&hospi1) != HAL_OK)
  {
    Error_Handler();
  }

}

static void MX_SAI1_Init(void)
{

  hsai_BlockA1.Instance = SAI1_Block_A;
  hsai_BlockA1.Init.Protocol = SAI_FREE_PROTOCOL;
  hsai_BlockA1.Init.AudioMode = SAI_MODEMASTER_RX;
  hsai_BlockA1.Init.DataSize = SAI_DATASIZE_8;
  hsai_BlockA1.Init.FirstBit = SAI_FIRSTBIT_MSB;
  hsai_BlockA1.Init.ClockStrobing = SAI_CLOCKSTROBING_FALLINGEDGE;
  hsai_BlockA1.Init.Synchro = SAI_ASYNCHRONOUS;
  hsai_BlockA1.Init.OutputDrive = SAI_OUTPUTDRIVE_DISABLE;
  hsai_BlockA1.Init.NoDivider = SAI_MASTERDIVIDER_ENABLE;
  hsai_BlockA1.Init.FIFOThreshold = SAI_FIFOTHRESHOLD_EMPTY;
  hsai_BlockA1.Init.AudioFrequency = SAI_AUDIO_FREQUENCY_96K;
  hsai_BlockA1.Init.MckOutput = SAI_MCK_OUTPUT_DISABLE;
  hsai_BlockA1.Init.MonoStereoMode = SAI_STEREOMODE;
  hsai_BlockA1.Init.CompandingMode = SAI_NOCOMPANDING;
  hsai_BlockA1.Init.PdmInit.Activation = ENABLE;
  hsai_BlockA1.Init.PdmInit.MicPairsNbr = 1;
  hsai_BlockA1.Init.PdmInit.ClockEnable = SAI_PDM_CLOCK1_ENABLE;
  hsai_BlockA1.FrameInit.FrameLength = 16;
  hsai_BlockA1.FrameInit.ActiveFrameLength = 1;
  hsai_BlockA1.FrameInit.FSDefinition = SAI_FS_STARTFRAME;
  hsai_BlockA1.FrameInit.FSPolarity = SAI_FS_ACTIVE_LOW;
  hsai_BlockA1.FrameInit.FSOffset = SAI_FS_FIRSTBIT;
  hsai_BlockA1.SlotInit.FirstBitOffset = 0;
  hsai_BlockA1.SlotInit.SlotSize = SAI_SLOTSIZE_DATASIZE;
  hsai_BlockA1.SlotInit.SlotNumber = 1;
  hsai_BlockA1.SlotInit.SlotActive = 0x0000FFFF;
  if (HAL_SAI_Init(&hsai_BlockA1) != HAL_OK)
  {
    Error_Handler();
  }

}

static void MX_TIM2_Init(void)
{

  TIM_ClockConfigTypeDef sClockSourceConfig = {0};
  TIM_MasterConfigTypeDef sMasterConfig = {0};
  TIM_IC_InitTypeDef sConfigIC = {0};

  htim2.Instance = TIM2;
  htim2.Init.Prescaler = 75-1;
  htim2.Init.CounterMode = TIM_COUNTERMODE_UP;
  htim2.Init.Period = 65535;
  htim2.Init.ClockDivision = TIM_CLOCKDIVISION_DIV1;
  htim2.Init.AutoReloadPreload = TIM_AUTORELOAD_PRELOAD_DISABLE;
  if (HAL_TIM_Base_Init(&htim2) != HAL_OK)
  {
    Error_Handler();
  }
  sClockSourceConfig.ClockSource = TIM_CLOCKSOURCE_INTERNAL;
  if (HAL_TIM_ConfigClockSource(&htim2, &sClockSourceConfig) != HAL_OK)
  {
    Error_Handler();
  }
  if (HAL_TIM_IC_Init(&htim2) != HAL_OK)
  {
    Error_Handler();
  }
  sMasterConfig.MasterOutputTrigger = TIM_TRGO_RESET;
  sMasterConfig.MasterSlaveMode = TIM_MASTERSLAVEMODE_DISABLE;
  if (HAL_TIMEx_MasterConfigSynchronization(&htim2, &sMasterConfig) != HAL_OK)
  {
    Error_Handler();
  }
  sConfigIC.ICPolarity = TIM_INPUTCHANNELPOLARITY_FALLING;
  sConfigIC.ICSelection = TIM_ICSELECTION_DIRECTTI;
  sConfigIC.ICPrescaler = TIM_ICPSC_DIV1;
  sConfigIC.ICFilter = 15;
  if (HAL_TIM_IC_ConfigChannel(&htim2, &sConfigIC, TIM_CHANNEL_1) != HAL_OK)
  {
    Error_Handler();
  }

}

static void MX_TIM3_Init(void)
{

  TIM_ClockConfigTypeDef sClockSourceConfig = {0};
  TIM_MasterConfigTypeDef sMasterConfig = {0};
  TIM_OC_InitTypeDef sConfigOC = {0};

  htim3.Instance = TIM3;
  htim3.Init.Prescaler = 250-1;
  htim3.Init.CounterMode = TIM_COUNTERMODE_UP;
  htim3.Init.Period = 17;
  htim3.Init.ClockDivision = TIM_CLOCKDIVISION_DIV1;
  htim3.Init.AutoReloadPreload = TIM_AUTORELOAD_PRELOAD_DISABLE;
  if (HAL_TIM_Base_Init(&htim3) != HAL_OK)
  {
    Error_Handler();
  }
  sClockSourceConfig.ClockSource = TIM_CLOCKSOURCE_INTERNAL;
  if (HAL_TIM_ConfigClockSource(&htim3, &sClockSourceConfig) != HAL_OK)
  {
    Error_Handler();
  }
  if (HAL_TIM_PWM_Init(&htim3) != HAL_OK)
  {
    Error_Handler();
  }
  sMasterConfig.MasterOutputTrigger = TIM_TRGO_RESET;
  sMasterConfig.MasterSlaveMode = TIM_MASTERSLAVEMODE_DISABLE;
  if (HAL_TIMEx_MasterConfigSynchronization(&htim3, &sMasterConfig) != HAL_OK)
  {
    Error_Handler();
  }
  sConfigOC.OCMode = TIM_OCMODE_PWM1;
  sConfigOC.Pulse = 0;
  sConfigOC.OCPolarity = TIM_OCPOLARITY_HIGH;
  sConfigOC.OCFastMode = TIM_OCFAST_DISABLE;
  if (HAL_TIM_PWM_ConfigChannel(&htim3, &sConfigOC, TIM_CHANNEL_2) != HAL_OK)
  {
    Error_Handler();
  }
  HAL_TIM_MspPostInit(&htim3);

}

static void MX_TIM16_Init(void)
{

  htim16.Instance = TIM16;
  htim16.Init.Prescaler = 75-1;
  htim16.Init.CounterMode = TIM_COUNTERMODE_UP;
  htim16.Init.Period = 65535;
  htim16.Init.ClockDivision = TIM_CLOCKDIVISION_DIV1;
  htim16.Init.RepetitionCounter = 0;
  htim16.Init.AutoReloadPreload = TIM_AUTORELOAD_PRELOAD_DISABLE;
  if (HAL_TIM_Base_Init(&htim16) != HAL_OK)
  {
    Error_Handler();
  }

}

static void MX_TIM17_Init(void)
{

  htim17.Instance = TIM17;
  htim17.Init.Prescaler = 75-1;
  htim17.Init.CounterMode = TIM_COUNTERMODE_UP;
  htim17.Init.Period = 65535;
  htim17.Init.ClockDivision = TIM_CLOCKDIVISION_DIV1;
  htim17.Init.RepetitionCounter = 0;
  htim17.Init.AutoReloadPreload = TIM_AUTORELOAD_PRELOAD_DISABLE;
  if (HAL_TIM_Base_Init(&htim17) != HAL_OK)
  {
    Error_Handler();
  }

}

static void MX_GPIO_Init(void)
{
  GPIO_InitTypeDef GPIO_InitStruct = {0};

  /* GPIO Ports Clock Enable */
  __HAL_RCC_GPIOE_CLK_ENABLE();
  __HAL_RCC_GPIOF_CLK_ENABLE();
  __HAL_RCC_GPIOC_CLK_ENABLE();
  __HAL_RCC_GPIOA_CLK_ENABLE();
  __HAL_RCC_GPIOB_CLK_ENABLE();
  __HAL_RCC_GPIOD_CLK_ENABLE();
  __HAL_RCC_GPIOG_CLK_ENABLE();

  /*Configure GPIO pin Output Level */
  HAL_GPIO_WritePin(GPIOE, USER_LED2_Pin|TRIG1_Pin, GPIO_PIN_RESET);

  /*Configure GPIO pin Output Level */
  HAL_GPIO_WritePin(SA0_LSM6D_GPIO_Port, SA0_LSM6D_Pin, GPIO_PIN_RESET);

  /*Configure GPIO pin Output Level */
  HAL_GPIO_WritePin(USER_LED1_GPIO_Port, USER_LED1_Pin, GPIO_PIN_RESET);

  /*Configure GPIO pins : USER_LED2_Pin TRIG1_Pin */
  GPIO_InitStruct.Pin = USER_LED2_Pin|TRIG1_Pin;
  GPIO_InitStruct.Mode = GPIO_MODE_OUTPUT_PP;
  GPIO_InitStruct.Pull = GPIO_NOPULL;
  GPIO_InitStruct.Speed = GPIO_SPEED_FREQ_LOW;
  HAL_GPIO_Init(GPIOE, &GPIO_InitStruct);

  /*Configure GPIO pins : INT1_LSM6D_Pin INT2_LSM6D_Pin */
  GPIO_InitStruct.Pin = INT1_LSM6D_Pin|INT2_LSM6D_Pin;
  GPIO_InitStruct.Mode = GPIO_MODE_IT_RISING;
  GPIO_InitStruct.Pull = GPIO_NOPULL;
  HAL_GPIO_Init(GPIOF, &GPIO_InitStruct);

  /*Configure GPIO pin : SA0_LSM6D_Pin */
  GPIO_InitStruct.Pin = SA0_LSM6D_Pin;
  GPIO_InitStruct.Mode = GPIO_MODE_OUTPUT_PP;
  GPIO_InitStruct.Pull = GPIO_NOPULL;
  GPIO_InitStruct.Speed = GPIO_SPEED_FREQ_LOW;
  HAL_GPIO_Init(SA0_LSM6D_GPIO_Port, &GPIO_InitStruct);

  /*Configure GPIO pin : ECHO1_Pin */
  GPIO_InitStruct.Pin = ECHO1_Pin;
  GPIO_InitStruct.Mode = GPIO_MODE_INPUT;
  GPIO_InitStruct.Pull = GPIO_NOPULL;
  HAL_GPIO_Init(ECHO1_GPIO_Port, &GPIO_InitStruct);

  /*Configure GPIO pin : USER_LED1_Pin */
  GPIO_InitStruct.Pin = USER_LED1_Pin;
  GPIO_InitStruct.Mode = GPIO_MODE_OUTPUT_PP;
  GPIO_InitStruct.Pull = GPIO_NOPULL;
  GPIO_InitStruct.Speed = GPIO_SPEED_FREQ_LOW;
  HAL_GPIO_Init(USER_LED1_GPIO_Port, &GPIO_InitStruct);

  /*Configure GPIO pin : USER_BUTTON_Pin */
  GPIO_InitStruct.Pin = USER_BUTTON_Pin;
  GPIO_InitStruct.Mode = GPIO_MODE_IT_RISING;
  GPIO_InitStruct.Pull = GPIO_NOPULL;
  HAL_GPIO_Init(USER_BUTTON_GPIO_Port, &GPIO_InitStruct);

  /* EXTI interrupt init*/
  HAL_NVIC_SetPriority(EXTI0_IRQn, 0, 0);
  HAL_NVIC_EnableIRQ(EXTI0_IRQn);

}

void HAL_TIM_PeriodElapsedCallback(TIM_HandleTypeDef *htim)
{
  if (htim->Instance == TIM6) {
    HAL_IncTick();
  }
  /* USER CODE BEGIN Callback 1 */
  if(htim->Instance == TIM17) {
     NEC_TX_SendMarkSpace();
  }

  /* USER CODE END Callback 1 */
}

void Error_Handler(void)
{
  /* USER CODE BEGIN Error_Handler_Debug */
  /* User can add his own implementation to report the HAL error return state */
  //__disable_irq();
  while (1)
  {
      HAL_Delay(150);
      HAL_GPIO_TogglePin(USER_LED1_GPIO_Port,USER_LED1_Pin);
  }
  /* USER CODE END Error_Handler_Debug */
}
